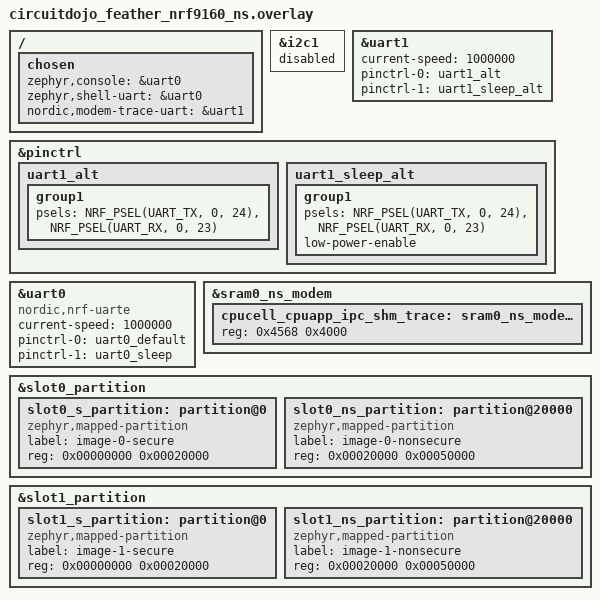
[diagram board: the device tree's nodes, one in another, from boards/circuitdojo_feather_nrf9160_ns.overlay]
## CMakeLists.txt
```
cmake_minimum_required(VERSION 3.20.0)

# This sample verifies the platform's certificate chain.
set(SAMPLE_TLS verify)
include(${CMAKE_CURRENT_SOURCE_DIR}/../common/app.cmake)

find_package(Zephyr REQUIRED HINTS $ENV{ZEPHYR_BASE})
project(ws_init)

include(${CMAKE_CURRENT_SOURCE_DIR}/../common/cert.cmake)

target_sources(app PRIVATE src/main.c src/shadow.c src/heap_monitor.c)

include(${CMAKE_CURRENT_SOURCE_DIR}/../common/net.cmake)
```

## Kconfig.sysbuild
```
rsource "../Kconfig.sysbuild.signing"

# An nRF91 application image is linked into a slot a bootloader jumps to, so a
# mass-erased Feather with nothing at address zero never starts. Every other
# board here boots its own image directly.
choice BOOTLOADER
	default BOOTLOADER_MCUBOOT if SOC_SERIES_NRF91
	default BOOTLOADER_NONE
endchoice

source "share/sysbuild/Kconfig"
```

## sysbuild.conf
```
# esp32c6_devkitc/Kconfig.sysbuild defaults BOOTLOADER to MCUBOOT (Espressif
# boards override the generic BOOTLOADER_NONE default -- unlike the nRF9160
# boards where MCUboot is opt-in). That default turned out to be broken in
# this Zephyr/MCUboot/NCS snapshot for a non-Nordic SoC: this workspace's
# `nrf` project (sdk-nrf) pulls in nrf/CMakeLists.txt unconditionally for
# every sysbuild image, including the MCUboot child image, and
# nrfxlib/common.cmake hard-asserts "GCC_M_CPU must be set to find correct
# lib" trying to resolve a Nordic-only crypto lib path for an SoC (esp32c6)
# nrfxlib has never heard of -- nrf/cmake/device_support.cmake even prints
# "SoC esp32c6 is not supported by this release" right before the assert
# fires. This isn't a pigeon-library gap or something to work around: it's
# NCS's own build machinery assuming Nordic-only SoCs workspace-wide, not
# just for images that need Nordic crypto. Explicitly override back to no
# bootloader (this sample doesn't need one -- see README) rather than
# chase that assertion; a real MCUboot/FOTA port to ESP32-C6 would need to
# resolve this at the west.yml/workspace level (e.g. a NCS release that
# added esp32c6 support, or excluding `nrf`'s CMakeLists coupling from
# non-Nordic sysbuild images), not from this sample.
SB_CONFIG_BOOTLOADER_NONE=y
```

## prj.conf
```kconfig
# The HTTPS connector plus a persistent WebSocket channel: the platform pushes
# a shadow the moment the dashboard writes one, and telemetry rides the socket
# that is already open. The endpoint and token belong in prj.local.conf.
CONFIG_PIGEON=y
CONFIG_PIGEON_CONNECTOR_HTTPS=y
CONFIG_PIGEON_WS=y
# The modem's credential store outlives a reflash and is keyed by tag, so each
# sample here owns a distinct one rather than the shared default.
CONFIG_PIGEON_HTTPS_SEC_TAG=43
# The upgrade handshake hashes its key with SHA-1; without this want
# websocket_connect() returns -EPROTO before a byte reaches the network.
CONFIG_PSA_WANT_ALG_SHA_1=y

# Diagnostics an operator runs from the dashboard over the same socket. A
# command that this image does not register answers -ENOEXEC however it is
# spelled here, so the list has to track what the build actually has.
CONFIG_PIGEON_SHELL=y
CONFIG_PIGEON_SHELL_ALLOWLIST="kernel version,kernel uptime"
# The backend's 300-byte default truncates anything past a one-line reply.
CONFIG_SHELL_BACKEND_DUMMY_BUF_SIZE=2048
# Shell commands arrive over the socket, not the console; the serial backend
# would redraw its prompt over every log line.
CONFIG_SHELL_BACKEND_SERIAL=n

CONFIG_PICOLIBC=y
CONFIG_STD_C17=y
CONFIG_MISRA_SANE=y
# What src/heap_monitor.c reads.
CONFIG_SYS_HEAP_RUNTIME_STATS=y

CONFIG_HEAP_MEM_POOL_SIZE=8192
CONFIG_MAIN_STACK_SIZE=8192
CONFIG_SYSTEM_WORKQUEUE_STACK_SIZE=4096
# Logging from the connection manager's event callbacks overflows the default.
CONFIG_NET_MGMT_EVENT_STACK_SIZE=2048

CONFIG_NETWORKING=y
CONFIG_NET_SOCKETS=y
CONFIG_NET_SOCKETS_SOCKOPT_TLS=y
CONFIG_NET_IPV4=y
CONFIG_NET_IPV6=y
CONFIG_NET_CONNECTION_MANAGER=y
CONFIG_NET_CONNECTION_MANAGER_MONITOR_STACK_SIZE=1024

CONFIG_LOG=y
CONFIG_LOG_DEFAULT_LEVEL=3
CONFIG_LOG_MODE_IMMEDIATE=y
# Lets the shadow's "log" field silence and restore logging at runtime.
CONFIG_LOG_RUNTIME_FILTERING=y
CONFIG_NET_LOG=y
```

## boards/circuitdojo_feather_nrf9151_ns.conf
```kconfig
# Beyond ../../common/boards/nrf91.conf.

# Modem trace on uart1 (see the overlay); the backend choice only applies
# once the trace subsystem itself is on.
CONFIG_NRF_MODEM_LIB_TRACE=y
CONFIG_NRF_MODEM_LIB_TRACE_BACKEND_UART=y
CONFIG_UART_1_ASYNC=y
CONFIG_UART_1_INTERRUPT_DRIVEN=n
```

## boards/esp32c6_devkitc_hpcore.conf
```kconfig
# Beyond ../../common/boards/esp32c6.conf.

# A rare assert inside the closed-source WiFi blob reaches Zephyr's fatal
# handler, whose default is to spin forever; reboot instead. The watchdog
# covers the other shape, a stall that never asserts at all.
CONFIG_PIGEON_REBOOT_ON_FATAL=y
CONFIG_PIGEON_WATCHDOG=y
```

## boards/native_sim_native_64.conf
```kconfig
# native_sim has no ESP32-C6 WiFi radio -- src/net/native_sim_connection_manager.c
# (selected by CMakeLists.txt for this board) swaps the real WiFi bring-up
# for a generic conn_mgr flow over Native Simulator offloaded sockets
# (NSOS), same rationale as coap_tcp_init's native_sim board conf: NSOS
# calls straight into the host's own BSD socket API, so DNS/routing/connect
# just use whatever this machine's network stack already does -- no
# net-setup.sh/root/TAP/NAT step needed at all. pigeon's HTTPS transport
# code, and every TLS/PSA fix below this file's own additions (still
# supplied by prj.conf, unchanged), are exactly what real ESP32-C6 hardware
# needed too -- this file only swaps out the network *bring-up*, the point
# of a native_sim variant being to exercise the platform protocol, not WiFi.

# CONFIG_WIFI is a plain bool (no board-forced default the way
# ETH_NATIVE_TAP is), so overriding it here is a normal .conf override, not
# a Kconfig "select" fight. WIFI_CREDENTIALS/_STATIC have no "depends on
# WIFI" of their own, but are disabled anyway since this board never reads
# them; ESP32_WIFI_DYNAMIC_RX_BUFFER_NUM lives under WIFI_ESP32's own
# Kconfig.esp32, unreachable once CONFIG_WIFI=n, so it's dropped rather than
# assigned to avoid an unsatisfied-dependency warning (fatal under this
# workspace's west-vanilla.yml build).
CONFIG_WIFI=n
CONFIG_WIFI_CREDENTIALS=n
CONFIG_WIFI_CREDENTIALS_STATIC=n

# No DHCP client either -- native_sim_connection_manager.c assigns a fixed
# dummy address itself (see its own comment for why conn_mgr needs one at
# all with NSOS's connectivity-sim interface).
CONFIG_NET_DHCPV4=n

CONFIG_ETH_NATIVE_TAP=n
CONFIG_NET_DRIVERS=y
CONFIG_NET_SOCKETS_OFFLOAD=y
CONFIG_NET_NATIVE_OFFLOADED_SOCKETS=y
CONFIG_NET_NATIVE_OFFLOADED_SOCKETS_CONNECTIVITY_SIM=y
```

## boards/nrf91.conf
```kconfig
# Both nRF91 Feathers, on top of ../../common/boards/nrf91.conf.

# Modem trace on uart1 (see the overlay); the backend choice only applies
# once the trace subsystem itself is on.
CONFIG_NRF_MODEM_LIB_TRACE=y
CONFIG_NRF_MODEM_LIB_TRACE_BACKEND_UART=y
CONFIG_UART_1_ASYNC=y
CONFIG_UART_1_INTERRUPT_DRIVEN=n
```

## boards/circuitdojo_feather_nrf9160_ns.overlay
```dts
/* i2c1 shares its peripheral instance with the trace UART below. */
&i2c1 {
  status = "disabled";
};

/* Modem trace UART. */
&uart1 {
  status = "okay";
  current-speed = <1000000>;
  pinctrl-0 = <&uart1_alt>;
  pinctrl-1 = <&uart1_sleep_alt>;
  pinctrl-names = "default", "sleep";
};

&pinctrl {
  uart1_alt: uart1_alt {
    group1 {
      psels = <NRF_PSEL(UART_TX, 0, 24)>,
        <NRF_PSEL(UART_RX, 0, 23)>;
  };
  };

  uart1_sleep_alt: uart1_sleep_alt {
    group1 {
      psels = <NRF_PSEL(UART_TX, 0, 24)>,
        <NRF_PSEL(UART_RX, 0, 23)>;
      low-power-enable;
  };
  };
};

&uart0 {
  status = "okay";
  compatible = "nordic,nrf-uarte";
  current-speed = <1000000>;
  pinctrl-0 = <&uart0_default>;
  pinctrl-1 = <&uart0_sleep>;
  pinctrl-names = "default", "sleep";
};

/* The modem trace buffer fits in the slack the stock partition file leaves
 * inside the modem shared-memory region, so nothing else has to move.
 * Nordic's own modem-trace snippet sizes it for a different SRAM total and
 * overflows this board. */
&sram0_ns_modem {
  cpucell_cpuapp_ipc_shm_trace: sram0_ns_modem@4568 {
    reg = <0x4568 0x4000>;
  };
};

/* The stock 256/192 KiB secure/non-secure split leaves TF-M most of its
 * share unused while this application overflows its own. The slot total is
 * unchanged, so MCUboot's overlay needs nothing. */
/delete-node/ &slot0_s_partition;
/delete-node/ &slot0_ns_partition;

&slot0_partition {
  slot0_s_partition: partition@0 {
    compatible = "zephyr,mapped-partition";
    label = "image-0-secure";
    reg = <0x00000000 0x00020000>;
  };

  slot0_ns_partition: partition@20000 {
    compatible = "zephyr,mapped-partition";
    label = "image-0-nonsecure";
    reg = <0x00020000 0x00050000>;
  };
};

/delete-node/ &slot1_s_partition;
/delete-node/ &slot1_ns_partition;

&slot1_partition {
  slot1_s_partition: partition@0 {
    compatible = "zephyr,mapped-partition";
    label = "image-1-secure";
    reg = <0x00000000 0x00020000>;
  };

  slot1_ns_partition: partition@20000 {
    compatible = "zephyr,mapped-partition";
    label = "image-1-nonsecure";
    reg = <0x00020000 0x00050000>;
  };
};

/ {
  chosen {
    zephyr,console = &uart0;
    zephyr,shell-uart = &uart0;
    nordic,modem-trace-uart = &uart1;
  };
};
```

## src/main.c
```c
#include <pigeon.h>
#include <zephyr/kernel.h>
#include <zephyr/logging/log.h>

#include "heap_monitor.h"
#include "net_connect.h"
#include "shadow.h"

LOG_MODULE_REGISTER(main);

/* The platform's root CA, terminated because mbedTLS parses PEM as a string. */
static const char ca_cert[] = {
#include "GTS_Root_R4.crt.hex"
    0x00
};

BUILD_ASSERT(sizeof(ca_cert) < KB(4), "the modem's credential store caps a certificate at 4 KiB");

int main(void) {
  int err = net_prepare();

  if (err) {
    return err;
  }

  err = net_install_ca(CONFIG_PIGEON_HTTPS_SEC_TAG, ca_cert, sizeof(ca_cert));
  if (err) {
    return err;
  }

  err = net_connect();
  if (err) {
    return err;
  }

  /* The endpoint and token come from Kconfig. device_id only names this
   * device in its own logs; the platform identifies it by its token. */
  struct pigeon_config config = {
      .device_id = "pigeon-ws-sample",
      .connector = {.type = PIGEON_CONNECTOR_HTTPS},
  };

  err = pigeon_init(&config);
  if (err) {
    net_disconnect();
    return err;
  }

  /* The socket only makes the loop react sooner, so a failure here costs
   * latency rather than function: shadow_loop() keeps polling over HTTPS. */
  err = pigeon_ws_start(shadow_ws_event_cb);
  if (err) {
    LOG_WRN("pigeon_ws_start() failed: %d; falling back to HTTPS polling", err);
  }

  heap_monitor_start();

  shadow_loop();

  return net_disconnect();
}
```

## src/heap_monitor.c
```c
/** @headerfile heap_monitor.h */
#include "heap_monitor.h"

#include <zephyr/kernel.h>
#include <zephyr/logging/log.h>
#include <zephyr/sys/sys_heap.h>

LOG_MODULE_REGISTER(heap_monitor);

/* The pool behind CONFIG_HEAP_MEM_POOL_SIZE, which a WiFi driver's receive
 * buffers and the network buffer pools draw from. No public header declares
 * it; the shell's own "kernel heap" command reads the same object this way. */
extern struct k_heap _system_heap;

#if defined(CONFIG_COMMON_LIBC_MALLOC) && CONFIG_COMMON_LIBC_MALLOC_ARENA_SIZE != 0
#define HEAP_MONITOR_LIBC 1
/* A second, separate arena: a vendor blob calling plain malloc() lands here
 * whatever the kernel-heap Kconfig says, so a crash in one is invisible in
 * the other. Declared here for the same reason as _system_heap above. */
extern int malloc_runtime_stats_get(struct sys_memory_stats* stats);
#endif

/* Frequent enough to catch a slide inside a short soak, sparse enough that a
 * multi-hour log stays greppable. */
#define HEAP_MONITOR_INTERVAL K_SECONDS(30)

static struct k_work_delayable heap_monitor_work;

static void heap_monitor_handler(struct k_work* work) {
  ARG_UNUSED(work);

  /* Uptime on every line, so the trend can be plotted from the console log
   * alone on a device with no wall clock. */
  uint32_t uptime_s = (uint32_t)(k_uptime_get() / 1000);

  struct sys_memory_stats stats;
  int err = sys_heap_runtime_stats_get(&_system_heap.heap, &stats);

  if (err) {
    LOG_ERR("sys_heap_runtime_stats_get failed: %d", err);
  } else {
    LOG_INF(
        "heap_stats uptime_s=%u free=%zu allocated=%zu max_allocated=%zu", uptime_s,
        stats.free_bytes, stats.allocated_bytes, stats.max_allocated_bytes
    );
  }

#if defined(HEAP_MONITOR_LIBC)
  struct sys_memory_stats libc_stats;
  int libc_err = malloc_runtime_stats_get(&libc_stats);

  if (libc_err) {
    LOG_ERR("malloc_runtime_stats_get failed: %d", libc_err);
  } else {
    LOG_INF(
        "libc_heap_stats uptime_s=%u free=%zu allocated=%zu max_allocated=%zu", uptime_s,
        libc_stats.free_bytes, libc_stats.allocated_bytes, libc_stats.max_allocated_bytes
    );
  }
#endif

  k_work_reschedule(&heap_monitor_work, HEAP_MONITOR_INTERVAL);
}

void heap_monitor_start(void) {
  k_work_init_delayable(&heap_monitor_work, heap_monitor_handler);
  k_work_reschedule(&heap_monitor_work, HEAP_MONITOR_INTERVAL);
}
```

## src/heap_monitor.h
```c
/** @file heap_monitor.h
 *  @brief Periodic heap logging, so a soak shows whether free memory trends
 *  down (a leak), stays flat while allocations still fail (fragmentation) or
 *  simply holds.
 */
#ifndef HEAP_MONITOR_H
#define HEAP_MONITOR_H

/** Starts the periodic log. Call once, after the network and the library are
 *  up, so the first sample is steady state rather than boot churn. */
void heap_monitor_start(void);

#endif
```

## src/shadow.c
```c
/** @headerfile shadow.h */
#include "shadow.h"

#include <pigeon.h>
#include <string.h>
#include <zephyr/data/json.h>
#include <zephyr/kernel.h>
#include <zephyr/logging/log.h>
#include <zephyr/logging/log_ctrl.h>
#include <zephyr/sys/printk.h>

#include "net_connect.h"

LOG_MODULE_REGISTER(shadow);

/* Given by the WebSocket worker thread, taken by shadow_loop(). */
static K_SEM_DEFINE(shadow_wakeup, 0, 1);

void shadow_ws_event_cb(enum pigeon_event ev, const struct pigeon_shadow_doc* shadow) {
  /* The pushed document only lives for this callback, so the loop re-fetches
   * over HTTPS rather than copying it out. A push is a wakeup, not a payload. */
  ARG_UNUSED(shadow);

  switch (ev) {
    case PIGEON_EVENT_CONNECTED:
      /* The server sends no snapshot on accept, so a fresh socket may mean
       * the platform moved on while this device was away. */
    case PIGEON_EVENT_SHADOW_UPDATE:
      k_sem_give(&shadow_wakeup);
      break;
    case PIGEON_EVENT_DISCONNECTED:
      /* The poll interval is the safety net while the socket is down. */
      break;
  }
}

/* target_config is opaque JSON to the library; this application decides what
 * its keys mean. */
struct app_shadow_config {
  bool log;
  int telemetry_interval;
  bool reboot;
};

static const struct json_obj_descr app_shadow_config_descr[] = {
    JSON_OBJ_DESCR_PRIM(struct app_shadow_config, log, JSON_TOK_TRUE),
    JSON_OBJ_DESCR_PRIM(struct app_shadow_config, telemetry_interval, JSON_TOK_NUMBER),
    JSON_OBJ_DESCR_PRIM(struct app_shadow_config, reboot, JSON_TOK_TRUE),
};

/* Defaults applied before the first sync of a boot. Nothing persists across
 * reboots, so every boot re-applies the platform's target from here. */
static struct app_shadow_config current_config = {
    .log = false,
    .telemetry_interval = 60,
    .reboot = false,
};

/* One call covers every module, so the shadow's "log" field really silences
 * and restores output. */
static void set_all_log_levels(uint32_t level) {
  uint32_t module_count = log_src_cnt_get(Z_LOG_LOCAL_DOMAIN_ID);

  for (uint32_t i = 0; i < module_count; i++) {
    log_filter_set(NULL, Z_LOG_LOCAL_DOMAIN_ID, (int16_t)i, level);
  }
}

/* Both keys ride one telemetry report, sent as a WebSocket frame while the
 * socket is up and an HTTPS POST otherwise. poll_count restarting at 1
 * doubles as a reboot indicator on the dashboard. */
static void report_telemetry(void) {
  static unsigned int poll_count;
  char buf[21];

  snprintk(buf, sizeof(buf), "%lld", (long long)(k_uptime_get() / 1000));

  int err = pigeon_telemetry_set("uptime_s", buf);

  snprintk(buf, sizeof(buf), "%u", ++poll_count);

  if (!err) {
    err = pigeon_telemetry_set("poll_count", buf);
  }

  if (!err) {
    err = pigeon_telemetry_flush();
  }

  if (err) {
    LOG_WRN("Telemetry report failed: %d", err);
  }
}

int shadow_sync(void) {
  struct pigeon_shadow_doc doc;
  int err = pigeon_shadow_get(&doc);

  if (err) {
    LOG_ERR("Failed to fetch device shadow: %d", err);
    return err;
  }

  LOG_INF(
      "Shadow fetched: target_version=%d current_version=%d updated_at=%lld", doc.target_version,
      doc.current_version, doc.updated_at
  );

  report_telemetry();

  if (doc.target_version == doc.current_version) {
    LOG_INF("Shadow already converged at version %d; nothing to apply", doc.current_version);
    return 0;
  }

  /* json_obj_parse() edits its input, and target_config only lives until the
   * next fetch. */
  char config_buf[CONFIG_PIGEON_SHADOW_CONFIG_MAX];

  strncpy(config_buf, doc.target_config, sizeof(config_buf) - 1);
  config_buf[sizeof(config_buf) - 1] = '\0';

  /* Keys absent from a partial update keep their current value. reboot is a
   * one-shot command and always starts false. */
  struct app_shadow_config target = current_config;
  target.reboot = false;

  int64_t decoded = json_obj_parse(
      config_buf, strlen(config_buf), app_shadow_config_descr, ARRAY_SIZE(app_shadow_config_descr),
      &target
  );

  if (decoded < 0) {
    LOG_ERR("Failed to parse shadow target_config '%s': %lld", doc.target_config, decoded);
    return (int)decoded;
  }

  if (target.log != current_config.log) {
    LOG_INF(
        "Shadow v%d: log %s -> %s", doc.target_version, current_config.log ? "true" : "false",
        target.log ? "true" : "false"
    );
    set_all_log_levels(target.log ? CONFIG_LOG_DEFAULT_LEVEL : LOG_LEVEL_NONE);
  }

  if (target.telemetry_interval != current_config.telemetry_interval) {
    LOG_INF(
        "Shadow v%d: telemetry_interval %d -> %d", doc.target_version,
        current_config.telemetry_interval, target.telemetry_interval
    );
  }

  current_config.log = target.log;
  current_config.telemetry_interval = target.telemetry_interval;

  LOG_INF(
      "Applied shadow v%d: log=%s telemetry_interval=%d", doc.target_version,
      current_config.log ? "true" : "false", current_config.telemetry_interval
  );

  char report_buf[128];
  int encode_err = json_obj_encode_buf(
      app_shadow_config_descr, ARRAY_SIZE(app_shadow_config_descr), &current_config, report_buf,
      sizeof(report_buf)
  );

  if (encode_err) {
    LOG_ERR("Failed to encode current_config for shadow report: %d", encode_err);
  } else {
    int report_err = pigeon_shadow_report(doc.target_version, report_buf);

    if (report_err) {
      LOG_WRN("Shadow report-back failed: %d", report_err);
    } else {
      LOG_INF("Reported current_config back to platform at v%d", doc.target_version);
    }
  }

  /* "reboot" is a command, not state: kept out of current_config so it is
   * never seen as unchanged and re-run on every poll. The CLOSE frame and the
   * network teardown both come first, so the server sees a clean disconnect
   * instead of waiting out a dead socket, and a modem is powered off rather
   * than reset. */
  if (target.reboot) {
    LOG_WRN("Shadow v%d requested reboot; disconnecting and rebooting now", doc.target_version);
    pigeon_ws_stop();
    net_disconnect();
    pigeon_reboot();
  }

  return 0;
}

void shadow_loop(void) {
  while (1) {
    shadow_sync();

    /* The interval is a ceiling, not a cadence: a pushed shadow or a fresh
     * connection collapses the wait to the round trip that carried it. */
    LOG_INF("Next shadow poll in <=%d s, sooner on a push", current_config.telemetry_interval);
    k_sem_take(&shadow_wakeup, K_SECONDS(current_config.telemetry_interval));
  }
}
```

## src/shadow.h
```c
/** @file shadow.h
 *  @brief Shadow sync: fetch, apply, report back, plus telemetry.
 */
#ifndef SHADOW_H
#define SHADOW_H

#include <pigeon.h>

/** Wakes shadow_loop() so a pushed shadow is applied without waiting out the
 *  poll interval. Runs on the WebSocket worker thread, so it only signals. */
void shadow_ws_event_cb(enum pigeon_event ev, const struct pigeon_shadow_doc* shadow);

/** Fetches the shadow, applies a newer target_config and reports the result.
 *  Returns 0 whether or not anything changed, negative on a transport or
 *  parse failure. */
int shadow_sync(void);

/** Runs shadow_sync() forever, waiting the shadow's own telemetry_interval
 *  between polls or until the platform pushes an update. */
void shadow_loop(void);

#endif
```
